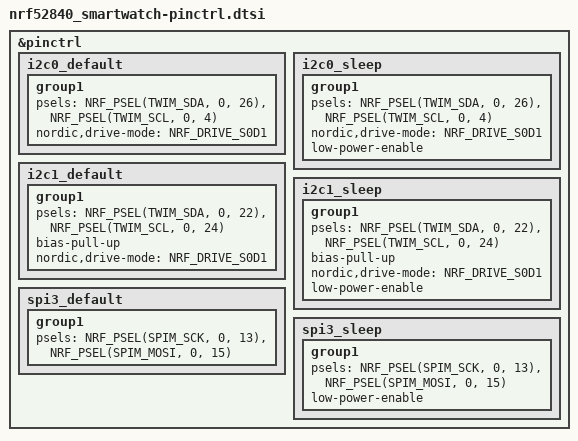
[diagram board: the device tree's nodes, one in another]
&pinctrl {
    i2c0_default: i2c0_default {
        group1 {
            psels = <NRF_PSEL(TWIM_SDA, 0, 26)>,
                    <NRF_PSEL(TWIM_SCL, 0, 4)>;
            nordic,drive-mode = <NRF_DRIVE_S0D1>;
        };
    };

    i2c0_sleep: i2c0_sleep {
        group1 {
            psels = <NRF_PSEL(TWIM_SDA, 0, 26)>,
                    <NRF_PSEL(TWIM_SCL, 0, 4)>;
            nordic,drive-mode = <NRF_DRIVE_S0D1>;
            low-power-enable;
        };
    };

    i2c1_default: i2c1_default {
        group1 {
            psels = <NRF_PSEL(TWIM_SDA, 0, 22)>,
                    <NRF_PSEL(TWIM_SCL, 0, 24)>;
            bias-pull-up;
            nordic,drive-mode = <NRF_DRIVE_S0D1>;
        };
    };

    i2c1_sleep: i2c1_sleep {
        group1 {
            psels = <NRF_PSEL(TWIM_SDA, 0, 22)>,
                    <NRF_PSEL(TWIM_SCL, 0, 24)>;
            bias-pull-up;
            nordic,drive-mode = <NRF_DRIVE_S0D1>;
            low-power-enable;
        };
    };

    spi3_default: spi3_default {
        group1 {
            psels = <NRF_PSEL(SPIM_SCK, 0, 13)>,
                    <NRF_PSEL(SPIM_MOSI, 0, 15)>;
        };
    };

    spi3_sleep: spi3_sleep {
        group1 {
            psels = <NRF_PSEL(SPIM_SCK, 0, 13)>,
                    <NRF_PSEL(SPIM_MOSI, 0, 15)>;
            low-power-enable;
        };
    };
};
